# MSP430FR2522 register map
Vendor: msp430gen; File version: v0.4.0-28-gb0087ce-dirty
Registers are 16-bit, read-write, reset 0x0 unless marked. A register's access mark holds for its fields unless they carry their own. Offsets are from the block's base; [hi:lo] are bit positions; lines under a group give offsets from that group; {n}, {i} and the like mark numbered series.

## MPY32
Base 0x000004C0
0x00 MPY — 16-bit operand one multiply
0x02 MPYS — 16-bit operand one signed multiply
0x04 MAC — 16-bit operand one multiply accumulate
0x06 MACS — 16-bit operand one signed multiply accumulate
0x08 OP2 — 16-bit operand two
0x0A RESLO — 16x16-bit result low word
0x0C RESHI — 16x16-bit result high word
0x0E SUMEXT — 16x16-bit sum extension register
0x10 MPY32L — 32-bit operand 1 multiply low word
0x12 MPY32H — 32-bit operand 1 multiply high word
0x14 MPYS32L — 32-bit operand 1 signed multiply low word
0x16 MPYS32H — 32-bit operand 1 signed multiply high word
0x18 MAC32L — 32-bit operand 1 multiply accumulate low word
0x1A MAC32H — 32-bit operand 1 multiply accumulate high word
0x1C MACS32L — 32-bit operand 1 signed multiply accumulate low word
0x1E MACS32H — 32-bit operand 1 signed multiply accumulate high word
0x20 OP2L — 32-bit operand 2 low word
0x22 OP2H — 32-bit operand 2 high word
0x24 RES0 — 32x32-bit result 0 least significant word
0x26 RES1 — 32x32-bit result 1
0x28 RES2 — 32x32-bit result 2
0x2A RES3 — 32x32-bit result 3 most significant word
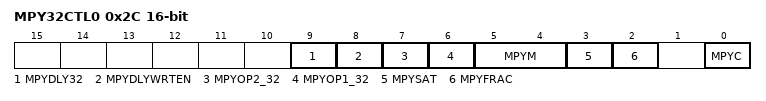
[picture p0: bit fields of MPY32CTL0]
0x2C MPY32CTL0 — MPY32 control register 0
  [9] MPYDLY32 — Delayed write mode.
    0=Writes are delayed until 64-bit result (RES0 to RES3) is available; 1=Writes are delayed until 32-bit result (RES0 to RES1) is available. 8 MPYDLYWRTEN
  [8] MPYDLYWRTEN — Delayed write enable.
    0=Writes are not delayed; 1=Writes are delayed
  [7] MPYOP2_32 — Multiplier bit width of operand 2
    0=16 bits; 1=32 bits
  [6] MPYOP1_32 — Multiplier bit width of operand 1
    0=16 bits; 1=32 bits
  [5:4] MPYM — Multiplier mode
    0=MPY (MPY Multiply); 1=MPYS (MPYS Signed multiply); 2=MAC (MAC Multiply accumulate); 3=MACS (MACS Signed multiply accumulate)
  [3] MPYSAT — Saturation mode
    0=DISABLE (Saturation mode disabled.); 1=ENABLE (Saturation mode enabled.)
  [2] MPYFRAC — Fractional mode.
    0=DISABLE (Fractional mode disabled.); 1=ENABLE (Fractional mode enabled.)
  [0] MPYC — Carry of the multiplier
    0=No carry for result; 1=Result has a carry

## BAKMEM
Base 0x00000660
0x00 BAKMEM0 — Backup Memory registers. Backup Memory 0.
{0x0+2i} BAKMEM{i} (i=1..9) — Backup Memory {i}.
0x14 BAKMEM10 — Backup Memory registers. Backup Memory 10.
{0x0+2i} BAKMEM{i} (i=11..15) — Backup Memory {i}.

## CAPTIVATE
Base 0x00000B20
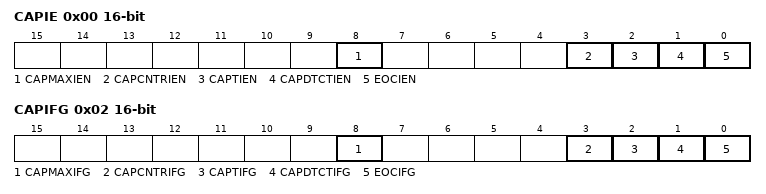
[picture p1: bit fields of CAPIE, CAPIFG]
0x00 CAPIE — Captivate Interrupt Enable Register
  [all] fields
    0=Interrupt disabled; 1=Interrupt enabled
  [8] CAPMAXIEN — Captivate maximum count interrupt enable
  [3] CAPCNTRIEN — Captivate Conversion Counter interrupt enable
  [2] CAPTIEN — Captivate Timer interrupt enable
  [1] CAPDTCTIEN — Captivate detection interrupt enable
  [0] EOCIEN — End of conversion interrupt enable
0x02 CAPIFG — Captivate Interrupt Flag Register
  [8] CAPMAXIFG — Captivate maximum count interrupt flag
    0=Maximum count not reached; 1=Maximum count reached
  [3] CAPCNTRIFG — Captivate conversion counter interrupt flag
    0=No interrupt pending; 1=Interrupt pending
  [2] CAPTIFG — Captivate timer interrupt flag
    0=No interrupt pending; 1=Interrupt pending
  [1] CAPDTCTIFG — Captivate detection interrupt flag
    0=No interrupt pending; 1=Interrupt pending
  [0] EOCIFG — End of conversion interrupt flag
    0=No end of conversion has occurred; 1=End of conversion has occurred
0x04 CAPIV — Captivate Interrupt Vector Register
  [15:0] CAPIV ro — Captivate interrupt vector value. Reading clears the highest priority interrupt, writing clears all pending interrupts
    0=No interrupt pending; 2=Interrupt source: End of conversion interrupt, Flag = EOCIFG; 4=Interrupt source: Detection interrupt, Flag = CAPDTCTIFG; 6=Interrupt source: Captivate Timer interrupt, Flag = CAPTIFG; 8=Interrupt source: Captivate Counter interrupt, Flag = CAPCNTRIFG; 10=Interrupt source: max count value reached, Flag = CAPMAXIFG

## TLV — Device descriptors (TLV)
Base 0x00001A00
0x00 INFO_LENGTH 8-bit ro
0x01 CRC_LENGTH 8-bit ro
0x02 CRC_VALUE ro — CRC value of the descriptors from 1A04h to 1AF5h (CRC-CCITT)
0x04 DEVICE_ID ro
{0x4+i} CRC_DATA[{i}] (i=0..241) 8-bit ro — Bytes 1A04h to 1AF5h, the range the CRC value covers
0x06 HW_REVISION 8-bit ro — Hardware revision
0x07 FW_REVISION 8-bit ro — Firmware revision
0x08 DIE_RECORD_TAG 8-bit ro
0x09 DIE_RECORD_LENGTH 8-bit ro
0x0A LOT_WAFER_ID 32-bit ro
0x0E DIE_X_POSITION ro
0x10 DIE_Y_POSITION ro
0x12 TEST_RESULT ro
0x14 ADC_CAL_TAG 8-bit ro — ADC calibration tag
0x15 ADC_CAL_LENGTH 8-bit ro — ADC calibration length
0x16 ADC_GAIN_FACTOR ro
0x18 ADC_OFFSET ro
{0x1A+4i} ADC_TEMP_CAL[{i}] (i=0..0) group — Temperature sensor calibration with the 1.5 V reference
  0x00 TEMP_30C ro — Temperature sensor ADC result at 30 degrees C
  0x02 TEMP_HIGH ro — Temperature sensor ADC result at 85 degrees C
0x1E REF_CAL_TAG 8-bit ro — REF calibration tag
0x1F REF_CAL_LENGTH 8-bit ro — REF calibration length
{0x20+2i} REF_FACTOR[{i}] (i=0..0) ro — Factor of the 1.5 V reference
0x22 DCO_TAP_16MHZ ro — DCO tap setting for 16 MHz
